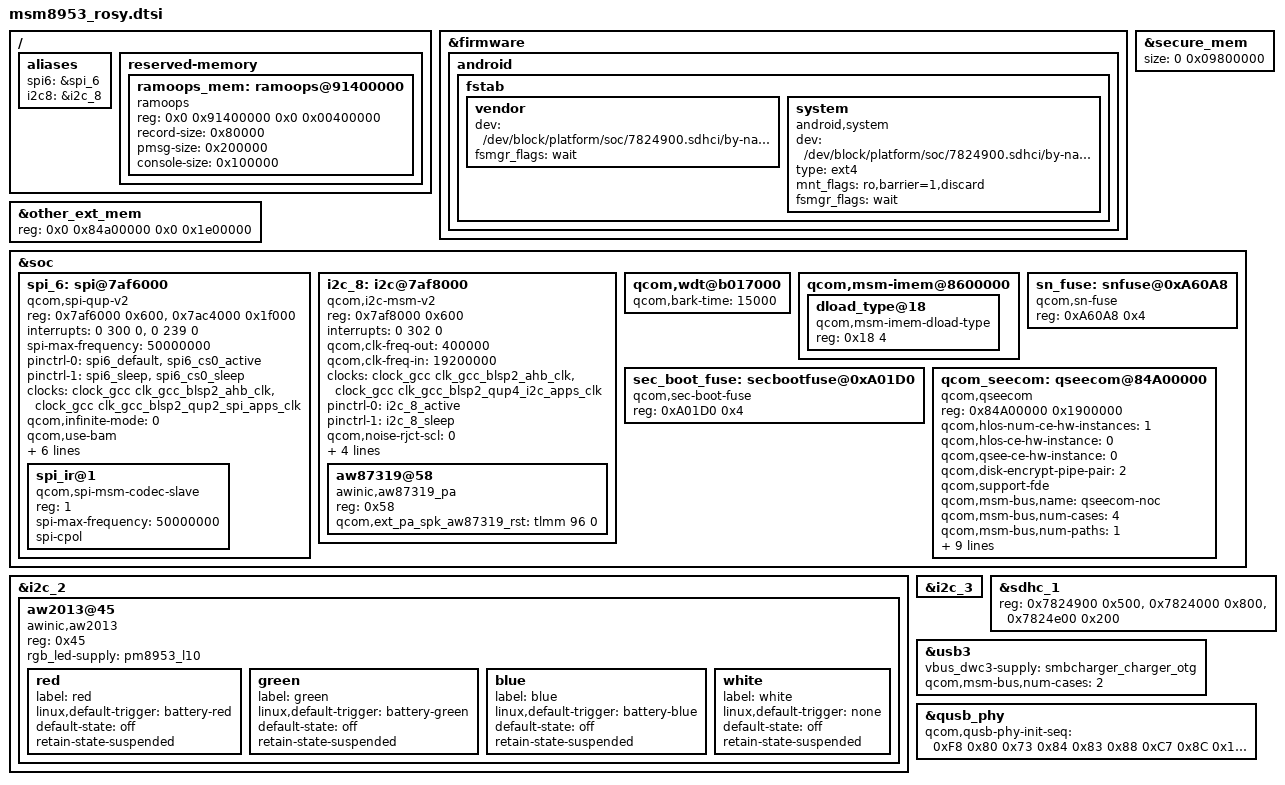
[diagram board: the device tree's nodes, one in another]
&firmware {
	android {
		fstab {
			vendor {
				dev = "/dev/block/platform/soc/7824900.sdhci/by-name/cust";
				fsmgr_flags = "wait";
			};

			system {
				compatible = "android,system";
				dev = "/dev/block/platform/soc/7824900.sdhci/by-name/system";
				type = "ext4";
				mnt_flags = "ro,barrier=1,discard";
				fsmgr_flags = "wait";
				status = "ok";
			};
		};
	};
};

&other_ext_mem { /* 0x1e00000 = 30 MiB */
	reg = <0x0 0x84a00000 0x0 0x1e00000>;
};

&secure_mem {
	size = <0 0x09800000>;
};

/ {
	aliases {
		spi6 = &spi_6;
		i2c8 = &i2c_8;
	};

	reserved-memory {
		ramoops_mem: ramoops@91400000 { /* 0x00400000 = 4 MiB */
			compatible = "ramoops";
			reg = <0x0 0x91400000 0x0 0x00400000>;

			record-size = <0x80000>;
			pmsg-size = <0x200000>;
			console-size = <0x100000>;
		};
	};
};

&soc {
	/delete-node/ qseecom@85b00000;

	spi_6: spi@7af6000 {
		compatible = "qcom,spi-qup-v2";
		#address-cells = <1>;
		#size-cells = <0>;
		reg-names = "spi_physical", "spi_bam_physical";
		reg = <0x7af6000 0x600>, <0x7ac4000 0x1f000>;
		interrupt-names = "spi_irq", "spi_bam_irq";
		interrupts = <0 300 0>, <0 239 0>;
		spi-max-frequency = <50000000>;
		pinctrl-names = "spi_default", "spi_sleep";
		pinctrl-0 = <&spi6_default &spi6_cs0_active>;
		pinctrl-1 = <&spi6_sleep &spi6_cs0_sleep>;
		clocks = <&clock_gcc clk_gcc_blsp2_ahb_clk>,
			 <&clock_gcc clk_gcc_blsp2_qup2_spi_apps_clk>;
		clock-names = "iface_clk", "core_clk";
		qcom,infinite-mode = <0>;
		qcom,use-bam;
		qcom,rt-priority;
		qcom,use-pinctrl;
		qcom,ver-reg-exists;
		qcom,bam-consumer-pipe-index = <6>;
		qcom,bam-producer-pipe-index = <7>;
		qcom,master-id = <84>;
		status = "ok";

		spi_ir@1 {
			compatible = "qcom,spi-msm-codec-slave";
			reg = <1>;
			spi-max-frequency = <50000000>;
			spi-cpol;
			status = "ok";
		};
	};

	i2c_8: i2c@7af8000 { /* BLSP2 QUP3 */
		compatible = "qcom,i2c-msm-v2";
		#address-cells = <1>;
		#size-cells = <0>;
		reg-names = "qup_phys_addr";
		reg = <0x7af8000 0x600>;
		interrupt-names = "qup_irq";
		interrupts = <0 302 0>;
		qcom,clk-freq-out = <400000>;
		qcom,clk-freq-in  = <19200000>;
		clock-names = "iface_clk", "core_clk";
		clocks = <&clock_gcc clk_gcc_blsp2_ahb_clk>,
			 <&clock_gcc clk_gcc_blsp2_qup4_i2c_apps_clk>;
		pinctrl-names = "i2c_active", "i2c_sleep";
		pinctrl-0 = <&i2c_8_active>;
		pinctrl-1 = <&i2c_8_sleep>;
		qcom,noise-rjct-scl = <0>;
		qcom,noise-rjct-sda = <0>;
		qcom,master-id = <84>;
		dmas = <&dma_blsp2 10 64 0x20000020 0x20>,
			<&dma_blsp2 11 32 0x20000020 0x20>;
		dma-names = "tx", "rx";

		aw87319@58 {
			compatible = "awinic,aw87319_pa";
			reg = <0x58>;
			qcom,ext_pa_spk_aw87319_rst = <&tlmm 96 0>;
		};
	};

	qcom,wdt@b017000 {
		qcom,bark-time = <15000>;
	};

	qcom,msm-imem@8600000 {
		/delete-node/ dload_type@1c;

		dload_type@18 {
			compatible = "qcom,msm-imem-dload-type";
			reg = <0x18 4>;
		};
	};

	sn_fuse: snfuse@0xA60A8 {
		compatible = "qcom,sn-fuse";
		reg = <0xA60A8 0x4>;
		reg-names = "sn-base";
	};

	sec_boot_fuse: secbootfuse@0xA01D0 {
		compatible = "qcom,sec-boot-fuse";
		reg = <0xA01D0 0x4>;
		reg-names = "sec-boot-base";
	};
	
	qcom_seecom: qseecom@84A00000 {
		compatible = "qcom,qseecom";
		reg = <0x84A00000 0x1900000>;
		reg-names = "secapp-region";
		qcom,hlos-num-ce-hw-instances = <1>;
		qcom,hlos-ce-hw-instance = <0>;
		qcom,qsee-ce-hw-instance = <0>;
		qcom,disk-encrypt-pipe-pair = <2>;
		qcom,support-fde;
		qcom,msm-bus,name = "qseecom-noc";
		qcom,msm-bus,num-cases = <4>;
		qcom,msm-bus,num-paths = <1>;
		qcom,support-bus-scaling;
		qcom,msm-bus,vectors-KBps =
			<55 512 0 0>,
			<55 512 0 0>,
			<55 512 120000 1200000>,
			<55 512 393600 3936000>;
		clocks = <&clock_gcc clk_crypto_clk_src>,
			 <&clock_gcc clk_gcc_crypto_clk>,
			 <&clock_gcc clk_gcc_crypto_ahb_clk>,
			 <&clock_gcc clk_gcc_crypto_axi_clk>;
		clock-names = "core_clk_src", "core_clk",
			      "iface_clk", "bus_clk";
		qcom,ce-opp-freq = <100000000>;
	};
};

&i2c_2 {
	/delete-node/ adv7533@39;

	aw2013@45 {
		compatible = "awinic,aw2013";
		reg = <0x45>;
		rgb_led-supply = <&pm8953_l10>;

		red {
			label = "red";
			linux,default-trigger = "battery-red";
			default-state = "off";
			retain-state-suspended;
		};

		green {
			label = "green";
			linux,default-trigger = "battery-green";
			default-state = "off";
			retain-state-suspended;
		};

		blue {
			label = "blue";
			linux,default-trigger = "battery-blue";
			default-state = "off";
			retain-state-suspended;
		};

		white {
			label = "white";
			linux,default-trigger = "none";
			default-state = "off";
			retain-state-suspended;
		};
	};
};

&i2c_3 {
	status = "okay";
};

&sdhc_1 {
	reg = <0x7824900 0x500>, <0x7824000 0x800>, <0x7824e00 0x200>;
	reg-names = "hc_mem", "core_mem", "cmdq_mem";
};

&usb3 {
	vbus_dwc3-supply = <&smbcharger_charger_otg>;
	qcom,msm-bus,num-cases = <2>;
};

&qusb_phy {
	qcom,qusb-phy-init-seq = <0xF8 0x80
				  0x73 0x84
				  0x83 0x88
				  0xC7 0x8C
				  0x14 0x9C
				  0x30 0x08
				  0x79 0x0C
				  0x21 0x10
				  0x00 0x90
				  0x9F 0x1C
				  0x00 0x18>;
};
